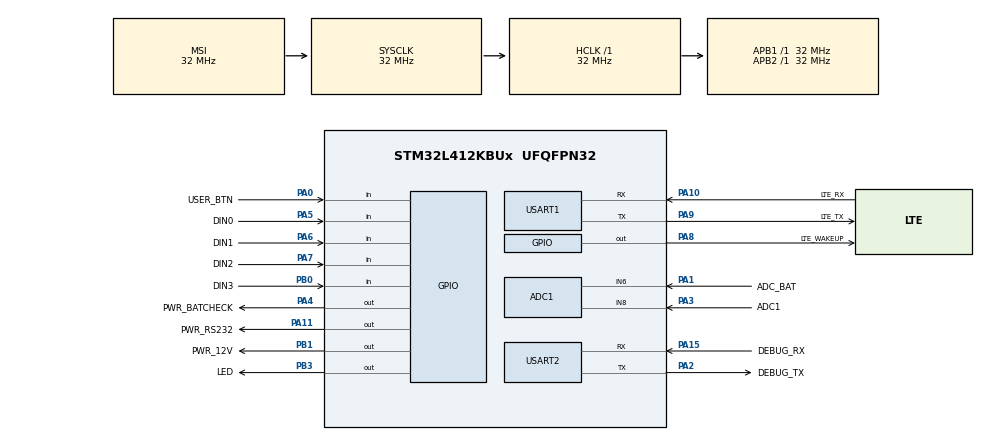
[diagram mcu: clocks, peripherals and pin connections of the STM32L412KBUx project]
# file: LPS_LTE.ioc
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ADC1.Channel-0\#ChannelRegularConversion=ADC_CHANNEL_6
ADC1.Channel-1\#ChannelRegularConversion=ADC_CHANNEL_8
ADC1.Channel-2\#ChannelRegularConversion=ADC_CHANNEL_VREFINT
ADC1.ClockPrescaler=ADC_CLOCK_ASYNC_DIV8
ADC1.ContinuousConvMode=DISABLE
ADC1.EnableInjectedConversion=DISABLE
ADC1.NbrOfConversion=3
ADC1.NbrOfConversionFlag=1
ADC1.OffsetNumber-0\#ChannelRegularConversion=ADC_OFFSET_NONE
ADC1.OffsetNumber-1\#ChannelRegularConversion=ADC_OFFSET_NONE
ADC1.OffsetNumber-2\#ChannelRegularConversion=ADC_OFFSET_NONE
ADC1.Rank-0\#ChannelRegularConversion=1
ADC1.Rank-1\#ChannelRegularConversion=2
ADC1.Rank-2\#ChannelRegularConversion=3
ADC1.SamplingTime-0\#ChannelRegularConversion=ADC_SAMPLETIME_6CYCLES_5
ADC1.SamplingTime-1\#ChannelRegularConversion=ADC_SAMPLETIME_6CYCLES_5
ADC1.SamplingTime-2\#ChannelRegularConversion=ADC_SAMPLETIME_6CYCLES_5
ADC1.master=1
Dma.ADC1.2.Direction=DMA_PERIPH_TO_MEMORY
Dma.ADC1.2.Instance=DMA1_Channel1
Dma.ADC1.2.MemDataAlignment=DMA_MDATAALIGN_HALFWORD
Dma.ADC1.2.MemInc=DMA_MINC_ENABLE
Dma.ADC1.2.Mode=DMA_CIRCULAR
Dma.ADC1.2.PeriphDataAlignment=DMA_PDATAALIGN_HALFWORD
Dma.ADC1.2.PeriphInc=DMA_PINC_DISABLE
Dma.ADC1.2.Priority=DMA_PRIORITY_LOW
Dma.Request0=USART1_RX
Dma.Request1=USART2_RX
Dma.Request2=ADC1
Dma.USART1_RX.0.Direction=DMA_PERIPH_TO_MEMORY
Dma.USART1_RX.0.Instance=DMA1_Channel5
Dma.USART1_RX.0.MemDataAlignment=DMA_MDATAALIGN_BYTE
Dma.USART1_RX.0.MemInc=DMA_MINC_ENABLE
Dma.USART1_RX.0.Mode=DMA_CIRCULAR
Dma.USART1_RX.0.PeriphDataAlignment=DMA_PDATAALIGN_BYTE
Dma.USART1_RX.0.PeriphInc=DMA_PINC_DISABLE
Dma.USART1_RX.0.Priority=DMA_PRIORITY_LOW
Dma.USART2_RX.1.Direction=DMA_PERIPH_TO_MEMORY
Dma.USART2_RX.1.Instance=DMA1_Channel6
Dma.USART2_RX.1.MemDataAlignment=DMA_MDATAALIGN_BYTE
Dma.USART2_RX.1.MemInc=DMA_MINC_ENABLE
Dma.USART2_RX.1.Mode=DMA_CIRCULAR
Dma.USART2_RX.1.PeriphDataAlignment=DMA_PDATAALIGN_BYTE
Dma.USART2_RX.1.PeriphInc=DMA_PINC_DISABLE
Dma.USART2_RX.1.Priority=DMA_PRIORITY_LOW
Mcu.Family=STM32L4
Mcu.Name=STM32L412KBUx
Mcu.Package=UFQFPN32
NVIC.DMA1_Channel1_IRQn=true\:0\:0\:false\:false\:true\:false\:true
NVIC.DMA1_Channel5_IRQn=true\:0\:0\:false\:false\:true\:false\:true
NVIC.DMA1_Channel6_IRQn=true\:0\:0\:false\:false\:true\:false\:true
NVIC.PriorityGroup=NVIC_PRIORITYGROUP_4
NVIC.RTC_WKUP_IRQn=true\:0\:0\:false\:false\:true\:true\:true
NVIC.TIM6_IRQn=true\:0\:0\:false\:false\:true\:true\:true
PA0-CK_IN.GPIO_Label=USER_BTN
PA0-CK_IN.Signal=GPIO_Input
PA1.GPIO_Label=ADC_BAT
PA1.Signal=ADCx_IN6
PA10.GPIO_Label=LTE_RX
PA10.Mode=Asynchronous
PA10.Signal=USART1_RX
PA11.GPIO_Label=PWR_RS232
PA11.Signal=GPIO_Output
PA13\ (JTMS/SWDIO).GPIO_Label=SWDIO
PA13\ (JTMS/SWDIO).Mode=Serial_Wire
PA13\ (JTMS/SWDIO).Signal=SYS_JTMS-SWDIO
PA14\ (JTCK/SWCLK).GPIO_Label=SWCLK
PA14\ (JTCK/SWCLK).Mode=Serial_Wire
PA14\ (JTCK/SWCLK).Signal=SYS_JTCK-SWCLK
PA15\ (JTDI).GPIO_Label=DEBUG_RX
PA15\ (JTDI).Mode=Asynchronous
PA15\ (JTDI).Signal=USART2_RX
PA2.GPIO_Label=DEBUG_TX
PA2.Mode=Asynchronous
PA2.Signal=USART2_TX
PA3.GPIO_Label=ADC1
PA3.Signal=ADCx_IN8
PA4.GPIO_Label=PWR_BATCHECK
PA4.Signal=GPIO_Output
PA5.GPIO_Label=DIN0
PA5.Signal=GPIO_Input
PA6.GPIO_Label=DIN1
PA6.Signal=GPIO_Input
PA7.GPIO_Label=DIN2
PA7.Signal=GPIO_Input
PA8.GPIO_Label=LTE_WAKEUP
PA8.Signal=GPIO_Output
PA9.GPIO_Label=LTE_TX
PA9.Mode=Asynchronous
PA9.Signal=USART1_TX
PB0.GPIO_Label=DIN3
PB0.Signal=GPIO_Input
PB1.GPIO_Label=PWR_12V
PB1.Signal=GPIO_Output
PB3\ (JTDO/TRACESWO).GPIO_Label=LED
PB3\ (JTDO/TRACESWO).Signal=GPIO_Output
PC14-OSC32_IN\ (PC14).Mode=LSE-External-Oscillator
PC14-OSC32_IN\ (PC14).Signal=RCC_OSC32_IN
PC15-OSC32_OUT\ (PC15).Mode=LSE-External-Oscillator
PC15-OSC32_OUT\ (PC15).Signal=RCC_OSC32_OUT
ProjectManager.HeapSize=0x200
ProjectManager.StackSize=0x400
ProjectManager.TargetToolchain=STM32CubeIDE
RCC.ADCFreq_Value=32000000
RCC.AHBFreq_Value=32000000
RCC.APB1Freq_Value=32000000
RCC.APB1TimFreq_Value=32000000
RCC.APB2Freq_Value=32000000
RCC.APB2TimFreq_Value=32000000
RCC.CortexFreq_Value=32000000
RCC.FLatency=FLASH_LATENCY_1
RCC.HCLKFreq_Value=32000000
RCC.HSE_VALUE=8000000
RCC.HSI48_VALUE=48000000
RCC.HSICalibrationValue=16
RCC.HSI_VALUE=16000000
RCC.MSIClockRange=RCC_MSIRANGE_10
RCC.MSI_VALUE=32000000
RCC.SYSCLKFreq_VALUE=32000000
RCC.USBFreq_Value=32000000
RCC.VCOOutputFreq_Value=256000000
RTC.AsynchPrediv=128-1
RTC.SynchPrediv=250-1
RTC.WakeUpClock=RTC_WAKEUPCLOCK_CK_SPRE_16BITS
RTC.WakeUpCounter=0xFFFF
SH.ADCx_IN6.0=ADC1_IN6,IN6-Single-Ended
SH.ADCx_IN8.0=ADC1_IN8,IN8-Single-Ended
TIM6.Period=1000-1
TIM6.Prescaler=32-1
USART1.VirtualMode-Asynchronous=VM_ASYNC
USART2.VirtualMode-Asynchronous=VM_ASYNC
VP_ADC1_Vref_Input.Mode=IN-Vrefint
VP_RTC_VS_RTC_Activate.Mode=RTC_Enabled
VP_RTC_VS_RTC_WakeUp_intern.Mode=WakeUp
VP_TIM6_VS_ClockSourceINT.Mode=Enable_Timer
board=NUCLEO-L412KB

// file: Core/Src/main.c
/* USER CODE BEGIN Header */
/**
  ******************************************************************************
  * @file           : main.c
  * @brief          : Main program body
  ******************************************************************************
  * @attention
  *
  * <h2><center>&copy; Copyright (c) 2020 STMicroelectronics.
  * All rights reserved.</center></h2>
  *
  * This software component is licensed by ST under BSD 3-Clause license,
  * the "License"; You may not use this file except in compliance with the
  * License. You may obtain a copy of the License at:
  *                        opensource.org/licenses/BSD-3-Clause
  *
  ******************************************************************************
  */
/* USER CODE END Header */
#include "main.h"
#include "adc.h"
#include "dma.h"
#include "rtc.h"
#include "tim.h"
#include "usart.h"
#include "gpio.h"

/* USER CODE BEGIN Includes */
#include "user.h"
/* USER CODE END Includes */

void SystemClock_Config(void);

int main(void)
{

  /* MCU Configuration--------------------------------------------------------*/

  /* Reset of all peripherals, Initializes the Flash interface and the Systick. */
  HAL_Init();

  /* Configure the system clock */
  SystemClock_Config();

  /* Initialize all configured peripherals */
  MX_GPIO_Init();
  MX_DMA_Init();
  MX_USART1_UART_Init();
  MX_USART2_UART_Init();
  MX_ADC1_Init();
  MX_RTC_Init();
  MX_TIM6_Init();

  /* Infinite loop */
  /* USER CODE BEGIN WHILE */
  userStart();
  while (1)
  {
	userLoop();
    /* USER CODE END WHILE */

  }
}

void SystemClock_Config(void)
{
  RCC_OscInitTypeDef RCC_OscInitStruct = {0};
  RCC_ClkInitTypeDef RCC_ClkInitStruct = {0};
  RCC_PeriphCLKInitTypeDef PeriphClkInit = {0};

  /** Configure LSE Drive Capability
  */
  HAL_PWR_EnableBkUpAccess();
  __HAL_RCC_LSEDRIVE_CONFIG(RCC_LSEDRIVE_LOW);
  /** Configure the main internal regulator output voltage
  */
  if (HAL_PWREx_ControlVoltageScaling(PWR_REGULATOR_VOLTAGE_SCALE1) != HAL_OK)
  {
    Error_Handler();
  }
  /** Initializes the RCC Oscillators according to the specified parameters
  * in the RCC_OscInitTypeDef structure.
  */
  RCC_OscInitStruct.OscillatorType = RCC_OSCILLATORTYPE_LSI|RCC_OSCILLATORTYPE_LSE
                              |RCC_OSCILLATORTYPE_MSI;
  RCC_OscInitStruct.LSEState = RCC_LSE_ON;
  RCC_OscInitStruct.LSIState = RCC_LSI_ON;
  RCC_OscInitStruct.MSIState = RCC_MSI_ON;
  RCC_OscInitStruct.MSICalibrationValue = 0;
  RCC_OscInitStruct.MSIClockRange = RCC_MSIRANGE_10;
  RCC_OscInitStruct.PLL.PLLState = RCC_PLL_NONE;
  if (HAL_RCC_OscConfig(&RCC_OscInitStruct) != HAL_OK)
  {
    Error_Handler();
  }
  /** Initializes the CPU, AHB and APB buses clocks
  */
  RCC_ClkInitStruct.ClockType = RCC_CLOCKTYPE_HCLK|RCC_CLOCKTYPE_SYSCLK
                              |RCC_CLOCKTYPE_PCLK1|RCC_CLOCKTYPE_PCLK2;
  RCC_ClkInitStruct.SYSCLKSource = RCC_SYSCLKSOURCE_MSI;
  RCC_ClkInitStruct.AHBCLKDivider = RCC_SYSCLK_DIV1;
  RCC_ClkInitStruct.APB1CLKDivider = RCC_HCLK_DIV1;
  RCC_ClkInitStruct.APB2CLKDivider = RCC_HCLK_DIV1;

  if (HAL_RCC_ClockConfig(&RCC_ClkInitStruct, FLASH_LATENCY_1) != HAL_OK)
  {
    Error_Handler();
  }
  PeriphClkInit.PeriphClockSelection = RCC_PERIPHCLK_RTC|RCC_PERIPHCLK_USART1
                              |RCC_PERIPHCLK_USART2|RCC_PERIPHCLK_ADC;
  PeriphClkInit.Usart1ClockSelection = RCC_USART1CLKSOURCE_PCLK2;
  PeriphClkInit.Usart2ClockSelection = RCC_USART2CLKSOURCE_PCLK1;
  PeriphClkInit.RTCClockSelection = RCC_RTCCLKSOURCE_LSI;
  if (HAL_RCCEx_PeriphCLKConfig(&PeriphClkInit) != HAL_OK)
  {
    Error_Handler();
  }
  /** Enable MSI Auto calibration
  */
  HAL_RCCEx_EnableMSIPLLMode();
}

void Error_Handler(void)
{
}

/************************ (C) COPYRIGHT STMicroelectronics *****END OF FILE****/
